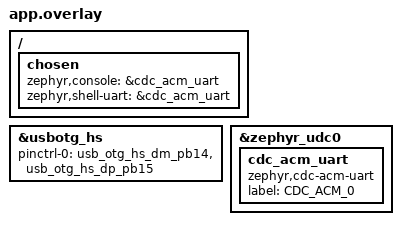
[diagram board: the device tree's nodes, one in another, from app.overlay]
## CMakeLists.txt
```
cmake_minimum_required(VERSION 3.20.0)
find_package(Zephyr REQUIRED HINTS $ENV{ZEPHYR_BASE})
project(trabalho_final)
target_sources(app PRIVATE src/main.c)
```

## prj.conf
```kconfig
# --- Habilitações Gerais de Subsistemas ---
CONFIG_GPIO=y
CONFIG_DEBUG=y

# --- Console, Serial e Shell ---
CONFIG_SERIAL=y
CONFIG_CONSOLE=y
CONFIG_SHELL=y
CONFIG_SHELL_LOG_BACKEND=y


# --- Stack USB e Console sobre USB (CDC_ACM) ---
CONFIG_USB_DEVICE_STACK=y
CONFIG_USB_DEVICE_PRODUCT="STM32F429 Hard Real-Time"
CONFIG_USB_CDC_ACM=y
CONFIG_USB_DEVICE_INITIALIZE_AT_BOOT=y

# --- Configurações de VID/PID para desenvolvimento ---
CONFIG_USB_DEVICE_VID=0x2FE3
CONFIG_USB_DEVICE_PID=0x0100
CONFIG_USB_DEVICE_MANUFACTURER="STM32F429 Hard RT"

# --- Módulos de Informação do Sistema ---
CONFIG_HEAP_MEM_POOL_SIZE=16384
CONFIG_THREAD_MONITOR=y
CONFIG_THREAD_NAME=y
CONFIG_THREAD_STACK_INFO=y
CONFIG_THREAD_ANALYZER=y
CONFIG_THREAD_ANALYZER_USE_PRINTK=y

# --- Configurações de Scheduling (corrigidas) ---
CONFIG_SCHED_THREAD_USAGE=y
CONFIG_SCHED_THREAD_USAGE_ALL=y

# --- Logs e Debug ---
CONFIG_LOG=y


# --- Configurações de Tempo Real Otimizadas ---
CONFIG_TIMESLICING=y
CONFIG_TIMESLICE_SIZE=5

# --- Precisão de Timing para Hard Real-Time ---
CONFIG_SYS_CLOCK_HW_CYCLES_PER_SEC=168000000
CONFIG_TIMER_RANDOM_GENERATOR=n
# CONFIG_TIMER_READS_ITS_FREQUENCY_AT_RUNTIME=y  # Removido - não existe

# --- Matemática e Geração de Números Aleatórios ---
CONFIG_ENTROPY_GENERATOR=y
CONFIG_TEST_RANDOM_GENERATOR=y

# --- Configurações de Memória Otimizadas ---
CONFIG_MAIN_STACK_SIZE=2048
CONFIG_CBPRINTF_FP_SUPPORT=y
CONFIG_KERNEL_MEM_POOL=y


# --- Configurações para reduzir latência ---
CONFIG_BOOT_BANNER=n
CONFIG_THREAD_CUSTOM_DATA=y

# --- Configurações de Floating Point ---
CONFIG_FPU=y
CONFIG_FPU_SHARING=y

# --- Configurações básicas para Hard Real-Time ---
# Configurações de Timer do Sistema
CONFIG_TICKLESS_KERNEL=y

# Configurações de Interrupções  
CONFIG_DYNAMIC_INTERRUPTS=y

# Configurações de Memória para Real-Time
CONFIG_MPU_STACK_GUARD=y
```

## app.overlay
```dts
/ {
	chosen {
		zephyr,console = &cdc_acm_uart;
		zephyr,shell-uart = &cdc_acm_uart;
	};
};

&usbotg_hs {
	pinctrl-0 = <&usb_otg_hs_dm_pb14 &usb_otg_hs_dp_pb15>;
	pinctrl-names = "default";
	status = "okay";
};

&zephyr_udc0 {
	cdc_acm_uart: cdc_acm_uart {
		compatible = "zephyr,cdc-acm-uart";
		label = "CDC_ACM_0";
	};
};
```

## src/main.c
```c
#include <zephyr/kernel.h>
#include <zephyr/drivers/gpio.h>
#include <zephyr/usb/usb_device.h>
#include <zephyr/logging/log.h>

LOG_MODULE_REGISTER(main, LOG_LEVEL_INF);

/* --- REFERÊNCIAS EXTERNAS --- */
extern int init_hard_realtime_filter(void);

/* --- TAREFA 1: PISCAR O LED (BAIXA PRIORIDADE) --- */
#define LED0_NODE DT_ALIAS(led0)
static const struct gpio_dt_spec led = GPIO_DT_SPEC_GET(LED0_NODE, gpios);

void blink_led_task(void)
{
    if (!gpio_is_ready_dt(&led)) {
        LOG_ERR("LED0 não está pronto");
        return;
    }
    
    gpio_pin_configure_dt(&led, GPIO_OUTPUT_ACTIVE);
    LOG_INF("LED de status iniciado");
    
    while (1) {
        gpio_pin_toggle_dt(&led);
        k_msleep(2000); // Pisca mais devagar para não interferir
    }
}

/* --- TAREFA 2: ACIONAMENTO PELO BOTÃO --- */
#define BUTTON0_NODE DT_ALIAS(sw0)
static const struct gpio_dt_spec button = GPIO_DT_SPEC_GET(BUTTON0_NODE, gpios);
static struct gpio_callback button_cb_data;
K_SEM_DEFINE(button_sem, 0, 1);

void button_pressed_callback(const struct device *dev, struct gpio_callback *cb, uint32_t pins)
{
    k_sem_give(&button_sem);
}

void button_action_task(void)
{
    uint32_t press_count = 0;
    
    while (1) {
        k_sem_take(&button_sem, K_FOREVER);
        press_count++;
        
        LOG_INF("Botao pressionado! Contagem: %u", press_count);
        
        // Indica pressionamento com LED por 100ms
        gpio_pin_set_dt(&led, 1);
        k_msleep(100);
        gpio_pin_set_dt(&led, 0);
        k_msleep(50);
        k_sem_reset(&button_sem);


    }
}

/* --- FUNÇÃO PRINCIPAL --- */
int main(void)
{
    // 1. Inicializa filtro hard real-time
    int ret = init_hard_realtime_filter();
    if (ret < 0) {
        LOG_ERR("Falha ao inicializar filtro hard real-time: %d", ret);
        LOG_ERR("Sistema continuara sem filtro hard real-time");
    } 
    
    // 2. Inicializa hardware do botão
    if (!gpio_is_ready_dt(&button)) {
        LOG_ERR("Botão não está pronto");
        return 0;
    }
    
    gpio_pin_configure_dt(&button, GPIO_INPUT);
    gpio_pin_interrupt_configure_dt(&button, GPIO_INT_EDGE_TO_ACTIVE);
    gpio_init_callback(&button_cb_data, button_pressed_callback, BIT(button.pin));
    gpio_add_callback(button.port, &button_cb_data);
    
    // 3. Sistema pronto!
    
   
    LOG_INF("Comandos shell disponiveis:");
    LOG_INF("  - 'sensor' - Comandos da tarefa soft real-time");
    LOG_INF("  - 'filter' - Comandos da tarefa hard real-time");
    LOG_INF("  - 'sysinfo' - Informacoes do sistema");
    
    return 0;
}

/* --- DEFINIÇÃO DAS THREADS COM PRIORIDADES HIERARQUICAS --- */
// Prioridade 2: Filtro hard real-time (definido em hard_realtime_filter.c)
// Prioridade 3: Amostragem ADC (definido em hard_realtime_filter.c)
// Prioridade 4: Sensor soft real-time (definido em sensor_task.c)
// Prioridade 7: Botão (responsividade)
// Prioridade 10: LED (menor prioridade)

K_THREAD_DEFINE(blink_led_tid, 512, blink_led_task, NULL, NULL, NULL, 10, 0, 0);
K_THREAD_DEFINE(button_action_tid, 512, button_action_task, NULL, NULL, NULL, 7, 0, 0);
```

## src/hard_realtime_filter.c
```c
#include <zephyr/kernel.h>
#include <zephyr/drivers/adc.h>
#include <zephyr/drivers/dac.h>
#include <zephyr/logging/log.h>
#include <zephyr/sys/ring_buffer.h>
#include <math.h>
#include <string.h>

LOG_MODULE_REGISTER(hard_filter, LOG_LEVEL_INF);

/* --- CONFIGURAÇÕES DO FILTRO HARD REAL-TIME --- */
#define SAMPLE_RATE_HZ 8000         // 8 kHz de amostragem
#define SAMPLE_PERIOD_US (1000000 / SAMPLE_RATE_HZ)  // 125 µs
#define HARD_DEADLINE_US 100        // Deadline rígido de 100µs
#define FILTER_ORDER 4              // Filtro IIR de 4ª ordem
#define CUTOFF_FREQ_HZ 1000         // Frequência de corte 1kHz

/* --- ESTRUTURAS DE DADOS --- */
struct filter_coeffs {
    float a[FILTER_ORDER + 1];      // Coeficientes do denominador
    float b[FILTER_ORDER + 1];      // Coeficientes do numerador
};

struct filter_state {
    float x[FILTER_ORDER + 1];      // Histórico de entradas
    float y[FILTER_ORDER + 1];      // Histórico de saídas
    uint32_t index;                 // Índice circular
};

/* --- CONFIGURAÇÃO DO HARDWARE --- */
#define ADC_NODE DT_ALIAS(adc)
#define DAC_NODE DT_ALIAS(dac)

#if DT_NODE_EXISTS(ADC_NODE)
static const struct device *adc_dev = DEVICE_DT_GET(ADC_NODE);
#endif

#if DT_NODE_EXISTS(DAC_NODE)
static const struct device *dac_dev = DEVICE_DT_GET(DAC_NODE);
#endif



/* --- VARIÁVEIS GLOBAIS --- */
static struct filter_coeffs coeffs;
static struct filter_state filter_state;
static struct k_timer sample_timer;
static K_SEM_DEFINE(sample_sem, 0, 1);
K_MSGQ_DEFINE(sample_msgq, sizeof(uint16_t), 32, 4);

/* --- ESTATÍSTICAS TEMPO REAL --- */
static uint32_t total_samples = 0;
static uint32_t missed_deadlines = 0;
static uint32_t max_processing_time_us = 0;
static uint32_t min_processing_time_us = UINT32_MAX;

/* --- INICIALIZAÇÃO DO FILTRO BUTTERWORTH PASSA-BAIXA --- */
static void init_butterworth_filter(void)
{
    // Coeficientes aproximados para filtro Butterworth 4ª ordem
    // Frequência de corte normalizada: fc/fs = 1000/8000 = 0.125
    // Estes são coeficientes aproximados para demonstração
    
    // Coeficientes do numerador (b)
    coeffs.b[0] = 0.0067f;
    coeffs.b[1] = 0.0268f;
    coeffs.b[2] = 0.0402f;
    coeffs.b[3] = 0.0268f;
    coeffs.b[4] = 0.0067f;
    
    // Coeficientes do denominador (a)
    coeffs.a[0] = 1.0000f;
    coeffs.a[1] = -2.3695f;
    coeffs.a[2] = 2.3140f;
    coeffs.a[3] = -1.0547f;
    coeffs.a[4] = 0.1874f;
    
    // Inicializa estado do filtro
    memset(&filter_state, 0, sizeof(filter_state));
    
    LOG_INF("Filtro Butterworth inicializado (fc=%d Hz, fs=%d Hz)", 
            CUTOFF_FREQ_HZ, SAMPLE_RATE_HZ);
}

/* --- APLICAÇÃO DO FILTRO IIR --- */
static float apply_filter(float input)
{
    uint32_t i = filter_state.index;
    
    // Armazena nova entrada
    filter_state.x[i] = input;
    
    // Calcula saída usando equação diferencial
    float output = 0.0f;
    
    // Parte do numerador (FIR)
    for (int n = 0; n <= FILTER_ORDER; n++) {
        uint32_t idx = (i + FILTER_ORDER - n) % (FILTER_ORDER + 1);
        output += coeffs.b[n] * filter_state.x[idx];
    }
    
    // Parte do denominador (IIR)
    for (int n = 1; n <= FILTER_ORDER; n++) {
        uint32_t idx = (i + FILTER_ORDER - n + 1) % (FILTER_ORDER + 1);
        output -= coeffs.a[n] * filter_state.y[idx];
    }
    
    // Armazena saída
    filter_state.y[i] = output;
    
    // Avança índice circular
    filter_state.index = (i + 1) % (FILTER_ORDER + 1);
    
    return output;
}

/* --- CALLBACK DO TIMER (INTERRUPT CONTEXT) --- */
static void sample_timer_handler(struct k_timer *timer)
{
    ARG_UNUSED(timer);
    // Sinaliza thread de processamento (não bloqueia)
    k_sem_give(&sample_sem);
}

/* --- TAREFA DE AMOSTRAGEM ADC (ALTA PRIORIDADE) --- */
static void adc_sampling_task(void *p1, void *p2, void *p3)
{
    ARG_UNUSED(p1);
    ARG_UNUSED(p2);
    ARG_UNUSED(p3);
    
#if DT_NODE_EXISTS(ADC_NODE)
    uint16_t sample_buffer[1];
    struct adc_sequence sequence = {
        .channels = BIT(0),
        .buffer = sample_buffer,
        .buffer_size = sizeof(sample_buffer),
        .resolution = 12,
        .oversampling = 0,
        .calibrate = false,
    };
    
    LOG_INF("Tarefa de amostragem ADC iniciada");
    
    while (1) {
        // Aguarda sinal do timer
        k_sem_take(&sample_sem, K_FOREVER);
        
        // Lê ADC (operação determinística)
        int ret = adc_read(adc_dev, &sequence);
        if (ret == 0) {
            // Envia amostra para processamento
            k_msgq_put(&sample_msgq, &sample_buffer[0], K_NO_WAIT);
        }
    }
#else
    while (1) {
        k_sem_take(&sample_sem, K_FOREVER);
        // Simula dados para teste
        uint16_t dummy_sample = 2048 + (total_samples % 100);
        k_msgq_put(&sample_msgq, &dummy_sample, K_NO_WAIT);
    }
#endif
}

/* --- TAREFA DE PROCESSAMENTO HARD REAL-TIME --- */
static void hard_realtime_filter_task(void *p1, void *p2, void *p3)
{
    ARG_UNUSED(p1);
    ARG_UNUSED(p2);
    ARG_UNUSED(p3);
    
    uint16_t raw_sample;
    uint32_t start_time, end_time, processing_time_us;
    
    LOG_INF("=== TAREFA HARD REAL-TIME INICIADA ===");
    LOG_INF("Deadline: %d us, Período: %d us", HARD_DEADLINE_US, SAMPLE_PERIOD_US);
    
    while (1) {
        // Aguarda nova amostra
        k_msgq_get(&sample_msgq, &raw_sample, K_FOREVER);
        
        start_time = k_cycle_get_32();
        
        // Converte ADC para float (-1.0 a 1.0)
        float input = (float)(raw_sample - 2048) / 2048.0f;
        
        // Aplica filtro digital
        float filtered = apply_filter(input);
        
        // Converte para DAC (0-4095)
        uint16_t dac_value = (uint16_t)((filtered + 1.0f) * 2048.0f);
        if (dac_value > 4095) dac_value = 4095;
        
        // Envia para DAC se disponível
#if DT_NODE_EXISTS(DAC_NODE)
        dac_write_value(dac_dev, 0, dac_value);
#endif
        
        end_time = k_cycle_get_32();
        processing_time_us = k_cyc_to_us_floor32(end_time - start_time);
        
        // Atualiza estatísticas
        total_samples++;
        if (processing_time_us > max_processing_time_us) {
            max_processing_time_us = processing_time_us;
        }
        if (processing_time_us < min_processing_time_us) {
            min_processing_time_us = processing_time_us;
        }
        
        // Verifica deadline HARD
        if (processing_time_us > HARD_DEADLINE_US) {
            missed_deadlines++;
            LOG_ERR("HARD DEADLINE PERDIDO! Amostra=%u, Tempo=%u us (limite=%u us)",
                    total_samples, processing_time_us, HARD_DEADLINE_US);
            
            // Em sistema real, seria necessário ação corretiva imediata
            // Por exemplo: reset do sistema, modo seguro, etc.
        }
        
        // Log periódico (sem afetar tempo real)
        //if ((total_samples % 1000) == 0) {
        //    LOG_INF("Amostras processadas: %u, Perdas: %u, Último tempo: %u us",
        //            total_samples, missed_deadlines, processing_time_us);
        //}
    }
}

/* --- FUNÇÕES DE INTERFACE PARA SHELL --- */
void get_filter_stats(uint32_t *total, uint32_t *missed, uint32_t *max_time, uint32_t *min_time)
{
    *total = total_samples;
    *missed = missed_deadlines;
    *max_time = max_processing_time_us;
    *min_time = (min_processing_time_us == UINT32_MAX) ? 0 : min_processing_time_us;
}

void get_filter_info(uint32_t *sample_rate, uint32_t *cutoff_freq, uint32_t *deadline_us)
{
    *sample_rate = SAMPLE_RATE_HZ;
    *cutoff_freq = CUTOFF_FREQ_HZ;
    *deadline_us = HARD_DEADLINE_US;
}

/* --- INICIALIZAÇÃO DO SISTEMA --- */
int init_hard_realtime_filter(void)
{
#if DT_NODE_EXISTS(ADC_NODE)
    /* --- E cole aqui, dentro do bloco #if --- */
    static const struct adc_channel_cfg adc_cfg = {
        .gain = ADC_GAIN_1,
        .reference = ADC_REF_INTERNAL,
        .acquisition_time = ADC_ACQ_TIME_DEFAULT,
        .channel_id = 0,
        .differential = 0,
    };

    if (!device_is_ready(adc_dev)) { ... }

    int ret = adc_channel_setup(adc_dev, &adc_cfg); // <-- Onde ela é usada
#else
    LOG_WRN("ADC não disponível - modo simulação");
#endif

#if DT_NODE_EXISTS(DAC_NODE)
    if (!device_is_ready(dac_dev)) {
        LOG_ERR("DAC não está pronto");
        return -ENODEV;
    }
    
    // Configura DAC
    struct dac_channel_cfg dac_cfg = {
        .channel_id = 0,
        .resolution = 12,
        .buffered = false,
    };
    
    ret = dac_channel_setup(dac_dev, &dac_cfg);
    if (ret < 0) {
        LOG_ERR("Erro ao configurar DAC: %d", ret);
        return ret;
    }
#else
    LOG_WRN("DAC não disponível - modo simulação");
#endif
    
    // Inicializa filtro
    init_butterworth_filter();
    
    // Inicializa timer
    k_timer_init(&sample_timer, sample_timer_handler, NULL);
    
    // Inicia timer periódico
    k_timer_start(&sample_timer, K_USEC(SAMPLE_PERIOD_US), K_USEC(SAMPLE_PERIOD_US));
    
    
    return 0;
}

/* --- DEFINIÇÃO DAS THREADS COM PRIORIDADES CRÍTICAS --- */
// Prioridade 2: Processamento hard real-time (mais alta)
// Prioridade 3: Amostragem ADC (alta)
K_THREAD_DEFINE(adc_sampling_tid, 1024, adc_sampling_task, NULL, NULL, NULL, 3, 0, 0);
K_THREAD_DEFINE(hard_filter_tid, 2048, hard_realtime_filter_task, NULL, NULL, NULL, 2, 0, 0);
```

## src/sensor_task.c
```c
// src/sensor_task.c - Uma tarefa de tempo real soft (com correções de warnings)
#include <zephyr/kernel.h>
#include <zephyr/drivers/gpio.h>
#include <zephyr/logging/log.h>
#include <zephyr/random/random.h>

LOG_MODULE_REGISTER(sensor_task, LOG_LEVEL_INF);

/* --- ESTRUTURA DE DADOS DO SENSOR --- */
struct sensor_reading {
    uint32_t timestamp;
    float temperature;
    float humidity;
    uint32_t sequence;
};

/* --- CONFIGURAÇÕES DA TAREFA TEMPO REAL SOFT --- */
#define SENSOR_PERIOD_MS 200        // 5Hz - leitura a cada 200ms
#define SENSOR_DEADLINE_MS 150      // Deadline de 150ms (soft real-time)
#define MAX_READINGS 50             // Buffer para últimas 50 leituras

/* --- VARIÁVEIS GLOBAIS --- */
static struct sensor_reading readings[MAX_READINGS];
static uint32_t reading_index = 0;
static uint32_t total_readings = 0;
static uint32_t missed_deadlines = 0;
static uint32_t max_processing_time_us = 0;

/* --- TAREFA DE LEITURA PERIÓDICA DE SENSORES (SOFT REAL-TIME) --- */
void sensor_reading_task(void)
{
    uint32_t start_time, processing_time;
    uint32_t next_period = k_uptime_get_32();
    
    LOG_INF("=== TAREFA SOFT REAL-TIME INICIADA ===");
    LOG_INF("Periodo: %d ms, Deadline: %d ms", SENSOR_PERIOD_MS, SENSOR_DEADLINE_MS);
    
    while (1) {
        start_time = k_cycle_get_32();
        
        // Simula leitura de sensores de temperatura e umidade
        struct sensor_reading *current = &readings[reading_index];
        
        current->timestamp = k_uptime_get_32();
        current->sequence = total_readings++;
        
        // Simula sensor de temperatura (20-30°C)
        current->temperature = 25.0f + (float)(sys_rand32_get() % 1000) / 100.0f - 5.0f;
        
        // Simula sensor de umidade (40-80%)
        current->humidity = 60.0f + (float)(sys_rand32_get() % 4000) / 100.0f - 20.0f;
        
        // Simula tempo de processamento variável (leitura I2C, ADC, etc.)
        // Tempo real soft: pode ocasionalmente perder deadline
        uint32_t processing_delay = sys_rand32_get() % 100000; // 0-100ms
        k_usleep(processing_delay); 

        
        // Calcula tempo de processamento
        processing_time = k_cycle_get_32() - start_time;
        uint32_t processing_time_us = k_cyc_to_us_floor32(processing_time);
        
        // Atualiza estatísticas
        if (processing_time_us > max_processing_time_us) {
            max_processing_time_us = processing_time_us;
        }
        
        // Verifica se perdeu o deadline (característica soft real-time)
        if (processing_time_us > (SENSOR_DEADLINE_MS * 1000)) {
            missed_deadlines++;
            LOG_WRN("Deadline perdido! Seq=%u, Tempo=%u us (limite=%u us)",
                    current->sequence, processing_time_us, SENSOR_DEADLINE_MS * 1000);
        }
        
        // Log periódico dos dados - CORREÇÃO: cast explícito para double
        //if ((total_readings % 10) == 0) {
        //    LOG_INF("Leitura #%u: T=%.1f°C, H=%.1f%%, tempo=%u us",
        //            current->sequence, (double)current->temperature, (double)current->humidity, processing_time_us);
        //}
        
        // Avança índice circular
        reading_index = (reading_index + 1) % MAX_READINGS;
        
        // Aguarda próximo período (característica periódica)
        next_period += SENSOR_PERIOD_MS;
        k_sleep(K_TIMEOUT_ABS_MS(next_period));
    }
}

/* --- FUNÇÃO PARA OBTER ESTATÍSTICAS (PARA O SHELL) --- */
void get_sensor_stats(uint32_t *total, uint32_t *missed, uint32_t *max_time_us)
{
    *total = total_readings;
    *missed = missed_deadlines;
    *max_time_us = max_processing_time_us;
}

/* --- FUNÇÃO PARA OBTER ÚLTIMA LEITURA --- */
struct sensor_reading* get_last_reading(void)
{
    if (total_readings == 0) {
        return NULL;
    }
    
    uint32_t last_index = (reading_index + MAX_READINGS - 1) % MAX_READINGS;
    return &readings[last_index];
}

/* --- FUNÇÃO PARA OBTER MÚLTIPLAS LEITURAS --- */
int get_recent_readings(struct sensor_reading *buffer, int max_count)
{
    int count = 0;
    int available = (total_readings < MAX_READINGS) ? total_readings : MAX_READINGS;
    
    if (available == 0) {
        return 0;
    }
    
    // Copia as leituras mais recentes
    for (int i = 0; i < available && count < max_count; i++) {
        int index = (reading_index + MAX_READINGS - 1 - i) % MAX_READINGS;
        buffer[count++] = readings[index];
    }
    
    return count;
}

/* --- DEFINIÇÃO DA THREAD COM PRIORIDADE ALTA (TEMPO REAL) --- */
K_THREAD_DEFINE(sensor_tid, 1024, sensor_reading_task, NULL, NULL, NULL, 4, 0, 0);
```

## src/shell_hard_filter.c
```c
// src/shell_hard_filter.c - Comandos shell para filtro hard real-time
#include <zephyr/kernel.h>
#include <zephyr/shell/shell.h>
#include <zephyr/logging/log.h>
#include <stdlib.h>
#include <math.h>
LOG_MODULE_REGISTER(shell_hard_filter, LOG_LEVEL_INF);

/* --- REFERÊNCIAS EXTERNAS --- */
extern void get_filter_stats(uint32_t *total, uint32_t *missed, uint32_t *max_time, uint32_t *min_time);
extern void get_filter_info(uint32_t *sample_rate, uint32_t *cutoff_freq, uint32_t *deadline_us);

/* --- COMANDO: ESTATÍSTICAS DO FILTRO HARD REAL-TIME --- */
static int cmd_filter_stats(const struct shell *sh, size_t argc, char **argv)
{
    uint32_t total, missed, max_time, min_time;
    get_filter_stats(&total, &missed, &max_time, &min_time);
    
    shell_print(sh, "=== ESTATISTICAS FILTRO HARD REAL-TIME ===");
    shell_print(sh, "Total de amostras: %u", total);
    shell_print(sh, "Deadlines perdidos: %u", missed);
    shell_print(sh, "Tempo processamento:");
    shell_print(sh, "  Minimo: %u us", min_time);
    shell_print(sh, "  Maximo: %u us", max_time);
    
    if (total > 0) {
        float miss_rate = (float)missed / total * 100.0f;
        shell_print(sh, "Taxa de perda: %.4f%%", (double)miss_rate);
        
        // Para hard real-time, QUALQUER perda é crítica
        if (missed == 0) {
            shell_print(sh, "Status: PERFEITO (0 perdas) - Hard Real-Time OK");
        } else {
            shell_print(sh, "Status: FALHA CRITICA (%u perdas) - Hard Real-Time VIOLADO", missed);
            shell_print(sh, "ACAO NECESSARIA: Sistema nao atende requisitos hard real-time");
        }
        
        // Análise do jitter
        if (max_time > 0 && min_time > 0) {
            uint32_t jitter = max_time - min_time;
            shell_print(sh, "Jitter: %u us", jitter);
            if (jitter > 20) {
                shell_print(sh, "AVISO: Jitter alto pode indicar problemas de determinismo");
            }
        }
    }
    
    return 0;
}

/* --- COMANDO: INFORMAÇÕES DO FILTRO --- */
static int cmd_filter_info(const struct shell *sh, size_t argc, char **argv)
{
    uint32_t sample_rate, cutoff_freq, deadline_us;
    get_filter_info(&sample_rate, &cutoff_freq, &deadline_us);
    
    shell_print(sh, "=== INFORMACOES DO FILTRO HARD REAL-TIME ===");
    shell_print(sh, "Tipo: Filtro IIR Butterworth passa-baixa");
    shell_print(sh, "Ordem: 4");
    shell_print(sh, "Frequencia de amostragem: %u Hz", sample_rate);
    shell_print(sh, "Frequencia de corte: %u Hz", cutoff_freq);
    shell_print(sh, "Periodo de amostragem: %u us", 1000000 / sample_rate);
    shell_print(sh, "Deadline HARD: %u us", deadline_us);
    shell_print(sh, "Prioridade: 2 (maxima)");
    
    shell_print(sh, "");
    shell_print(sh, "Caracteristicas Hard Real-Time:");
    shell_print(sh, "  - Deadline rigido de %u us", deadline_us);
    shell_print(sh, "  - Processamento deterministico");
    shell_print(sh, "  - Nenhuma perda de deadline tolerada");
    shell_print(sh, "  - Tempo de resposta garantido");
    shell_print(sh, "  - Preempcao de todas as outras tarefas");
    
    shell_print(sh, "");
    shell_print(sh, "Fluxo de dados:");
    shell_print(sh, "  ADC -> Filtro Digital -> DAC");
    
    return 0;
}

/* --- COMANDO: MONITORAMENTO EM TEMPO REAL --- */
static int cmd_filter_monitor(const struct shell *sh, size_t argc, char **argv)
{
    int duration = 10; // segundos
    
    if (argc > 1) {
        duration = atoi(argv[1]);
        if (duration < 5 || duration > 60) {
            shell_error(sh, "Duracao deve estar entre 5 e 60 segundos");
            return -EINVAL;
        }
    }
    
    shell_print(sh, "=== MONITORAMENTO HARD REAL-TIME (%d segundos) ===", duration);
    shell_print(sh, "Monitorando violacoes de deadline...");
    
    uint32_t start_time = k_uptime_get_32();
    uint32_t last_check = start_time;
    uint32_t last_total = 0;
    uint32_t last_missed = 0;
    
    while ((k_uptime_get_32() - start_time) < (duration * 1000)) {
        // Verifica estatísticas a cada segundo
        if ((k_uptime_get_32() - last_check) >= 1000) {
            uint32_t total, missed, max_time, min_time;
            get_filter_stats(&total, &missed, &max_time, &min_time);
            
            uint32_t new_samples = total - last_total;
            uint32_t new_missed = missed - last_missed;
            
            shell_print(sh, "T+%02d: Amostras=%u (+%u/s), Perdas=%u (+%u), Max=%uus, Min=%uus",
                       (k_uptime_get_32() - start_time) / 1000,
                       total, new_samples, missed, new_missed, max_time, min_time);
            
            if (new_missed > 0) {
                shell_print(sh, "     !!! VIOLACAO HARD REAL-TIME DETECTADA !!!");
            }
            
            last_check = k_uptime_get_32();
            last_total = total;
            last_missed = missed;
        }
        
        k_msleep(100);
    }
    
    shell_print(sh, "Monitoramento finalizado");
    
    // Relatório final
    uint32_t total, missed, max_time, min_time;
    get_filter_stats(&total, &missed, &max_time, &min_time);
    
    shell_print(sh, "");
    shell_print(sh, "=== RELATORIO FINAL ===");
    shell_print(sh, "Amostras processadas: %u", total);
    shell_print(sh, "Deadlines perdidos: %u", missed);
    shell_print(sh, "Taxa de amostragem media: %.1f Hz", (double)total / duration);
    
    if (missed == 0) {
        shell_print(sh, "RESULTADO: Sistema atende requisitos hard real-time");
    } else {
        shell_print(sh, "RESULTADO: Sistema FALHOU nos requisitos hard real-time");
    }
    
    return 0;
}

/* --- COMANDO: TESTE DE STRESS --- */
static int cmd_filter_stress(const struct shell *sh, size_t argc, char **argv)
{
    shell_print(sh, "=== TESTE DE STRESS HARD REAL-TIME ===");
    shell_print(sh, "Iniciando teste de stress por 30 segundos...");
    shell_print(sh, "Este teste adiciona carga ao sistema para verificar determinismo");
    
    // Cria carga adicional no sistema
    uint32_t start_time = k_uptime_get_32();
    uint32_t stress_count = 0;
    
    while ((k_uptime_get_32() - start_time) < 30000) {
        // Adiciona trabalho computacional
        volatile float dummy = 0.0f;
        for (int i = 0; i < 1000; i++) {
            dummy += sinf(i * 0.1f);
        }
        stress_count++;
        
        // Verifica estatísticas periodicamente
        if ((stress_count % 100) == 0) {
            uint32_t total, missed, max_time, min_time;
            get_filter_stats(&total, &missed, &max_time, &min_time);
            
            shell_print(sh, "Stress %u: Amostras=%u, Perdas=%u, Max=%uus",
                       stress_count, total, missed, max_time);
        }
        
        k_msleep(10);
    }
    
    shell_print(sh, "Teste de stress finalizado");
    
    uint32_t total, missed, max_time, min_time;
    get_filter_stats(&total, &missed, &max_time, &min_time);
    
    shell_print(sh, "");
    shell_print(sh, "=== RESULTADO DO TESTE DE STRESS ===");
    shell_print(sh, "Iteracoes de stress: %u", stress_count);
    shell_print(sh, "Amostras processadas: %u", total);
    shell_print(sh, "Deadlines perdidos: %u", missed);
    
    if (missed == 0) {
        shell_print(sh, "RESULTADO: Sistema mantem hard real-time sob stress");
    } else {
        shell_print(sh, "RESULTADO: Sistema perde hard real-time sob stress");
        shell_print(sh, "Necessario otimizar prioridades ou reduzir carga");
    }
    
    return 0;
}

/* --- COMANDO: ANÁLISE DE LATÊNCIA --- */
static int cmd_filter_latency(const struct shell *sh, size_t argc, char **argv)
{
    shell_print(sh, "=== ANALISE DE LATENCIA HARD REAL-TIME ===");
    
    uint32_t sample_rate, cutoff_freq, deadline_us;
    get_filter_info(&sample_rate, &cutoff_freq, &deadline_us);
    
    uint32_t total, missed, max_time, min_time;
    get_filter_stats(&total, &missed, &max_time, &min_time);
    
    shell_print(sh, "Deadline configurado: %u us", deadline_us);
    shell_print(sh, "Latencia minima: %u us", min_time);
    shell_print(sh, "Latencia maxima: %u us", max_time);
    
    if (total > 0) {
        uint32_t jitter = max_time - min_time;
        shell_print(sh, "Jitter: %u us", jitter);
        
        float deadline_margin = ((float)(deadline_us - max_time) / deadline_us) * 100.0f;
        shell_print(sh, "Margem de deadline: %.1f%%", (double)deadline_margin);
        
        shell_print(sh, "");
        shell_print(sh, "Analise de determinismo:");
        if (jitter < 10) {
            shell_print(sh, "  Jitter: EXCELENTE (< 10us)");
        } else if (jitter < 30) {
            shell_print(sh, "  Jitter: BOM (< 30us)");
        } else {
            shell_print(sh, "  Jitter: RUIM (> 30us) - Verificar sistema");
        }
        
        if (deadline_margin > 20.0f) {
            shell_print(sh, "  Margem: SEGURA (> 20%%)");
        } else if (deadline_margin > 10.0f) {
            shell_print(sh, "  Margem: ACEITAVEL (> 10%%)");
        } else {
            shell_print(sh, "  Margem: CRITICA (< 10%%) - Risco de violacao");
        }
    }
    
    return 0;
}

/* --- DEFINIÇÃO DOS SUBCOMANDOS --- */
SHELL_STATIC_SUBCMD_SET_CREATE(sub_filter,
    SHELL_CMD(stats, NULL, "Estatisticas do filtro hard real-time", cmd_filter_stats),
    SHELL_CMD(info, NULL, "Informacoes do filtro", cmd_filter_info),
    SHELL_CMD(monitor, NULL, "Monitor em tempo real [duracao_seg]", cmd_filter_monitor),
    SHELL_CMD(stress, NULL, "Teste de stress do sistema", cmd_filter_stress),
    SHELL_CMD(latency, NULL, "Analise de latencia e jitter", cmd_filter_latency),
    SHELL_SUBCMD_SET_END
);

/* --- REGISTRO DO COMANDO PRINCIPAL --- */
SHELL_CMD_REGISTER(filter, &sub_filter, "Comandos do filtro hard real-time", NULL);
```

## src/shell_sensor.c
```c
// src/shell_sensor.c - Comandos shell para a tarefa de sensor
#include <zephyr/kernel.h>
#include <zephyr/shell/shell.h>
#include <zephyr/logging/log.h>
#include <stdlib.h>  // Added for atoi function

LOG_MODULE_REGISTER(shell_sensor, LOG_LEVEL_INF);

/* --- REFERÊNCIAS EXTERNAS --- */
extern void get_sensor_stats(uint32_t *total, uint32_t *missed, uint32_t *max_time_us);
extern struct sensor_reading* get_last_reading(void);
extern int get_recent_readings(struct sensor_reading *buffer, int max_count);

struct sensor_reading {
    uint32_t timestamp;
    float temperature;
    float humidity;
    uint32_t sequence;
};

/* --- COMANDO: ESTATÍSTICAS DA TAREFA --- */
static int cmd_sensor_stats(const struct shell *sh, size_t argc, char **argv)
{
    uint32_t total, missed, max_time_us;
    get_sensor_stats(&total, &missed, &max_time_us);
    
    shell_print(sh, "=== ESTATISTICAS DA TAREFA SOFT REAL-TIME ===");
    shell_print(sh, "Total de leituras: %u", total);
    shell_print(sh, "Deadlines perdidos: %u", missed);
    shell_print(sh, "Tempo max processamento: %u us", max_time_us);
    
    if (total > 0) {
        float miss_rate = (float)missed / total * 100.0f;
        shell_print(sh, "Taxa de perda: %.2f%%", (double)miss_rate);  // Fixed: cast to double
        
        if (miss_rate < 5.0f) {
            shell_print(sh, "Status: EXCELENTE (< 5%% perdas)");
        } else if (miss_rate < 15.0f) {
            shell_print(sh, "Status: BOM (< 15%% perdas)");
        } else {
            shell_print(sh, "Status: ATENCAO (> 15%% perdas)");
        }
    }
    
    return 0;
}

/* --- COMANDO: ÚLTIMA LEITURA --- */
static int cmd_sensor_last(const struct shell *sh, size_t argc, char **argv)
{
    struct sensor_reading *reading = get_last_reading();
    
    if (reading == NULL) {
        shell_print(sh, "Nenhuma leitura disponivel ainda");
        return 0;
    }
    
    shell_print(sh, "=== ULTIMA LEITURA ===");
    shell_print(sh, "Sequencia: %u", reading->sequence);
    shell_print(sh, "Timestamp: %u ms", reading->timestamp);
    shell_print(sh, "Temperatura: %.1f °C", (double)reading->temperature);  // Fixed: cast to double
    shell_print(sh, "Umidade: %.1f %%", (double)reading->humidity);  // Fixed: cast to double
    shell_print(sh, "Idade: %u ms", k_uptime_get_32() - reading->timestamp);
    
    return 0;
}

/* --- COMANDO: MÚLTIPLAS LEITURAS --- */
static int cmd_sensor_history(const struct shell *sh, size_t argc, char **argv)
{
    int count = 5; // padrão: 5 leituras
    
    if (argc > 1) {
        count = atoi(argv[1]);
        if (count < 1 || count > 20) {
            shell_error(sh, "Numero de leituras deve estar entre 1 e 20");
            return -EINVAL;
        }
    }
    
    struct sensor_reading buffer[20];
    int readings_count = get_recent_readings(buffer, count);
    
    if (readings_count == 0) {
        shell_print(sh, "Nenhuma leitura disponivel");
        return 0;
    }
    
    shell_print(sh, "=== HISTORICO DE LEITURAS (ultimas %d) ===", readings_count);
    shell_print(sh, "Seq   | Timestamp | Temp(°C) | Umid(%%) | Idade(ms)");
    shell_print(sh, "------|-----------|----------|---------|----------");
    
    uint32_t current_time = k_uptime_get_32();
    for (int i = 0; i < readings_count; i++) {
        shell_print(sh, "%5u | %9u | %7.1f  | %6.1f  | %8u",
                    buffer[i].sequence, buffer[i].timestamp,
                    (double)buffer[i].temperature, (double)buffer[i].humidity,  // Fixed: cast to double
                    current_time - buffer[i].timestamp);
    }
    
    return 0;
}

/* --- COMANDO: INFORMAÇÕES DA TAREFA --- */
static int cmd_sensor_info(const struct shell *sh, size_t argc, char **argv)
{
    shell_print(sh, "=== INFORMACOES DA TAREFA SOFT REAL-TIME ===");
    shell_print(sh, "Tipo: Leitura periodica de sensores");
    shell_print(sh, "Periodo: 200 ms (5 Hz)");
    shell_print(sh, "Deadline: 150 ms (soft real-time)");
    shell_print(sh, "Prioridade: 4 (alta)");
    shell_print(sh, "Buffer: 50 leituras");
    shell_print(sh, "Sensores simulados:");
    shell_print(sh, "  - Temperatura: 20-30°C");
    shell_print(sh, "  - Umidade: 40-80%%");
    shell_print(sh, "Caracteristicas soft real-time:");
    shell_print(sh, "  - Pode ocasionalmente perder deadlines");
    shell_print(sh, "  - Degrada graciosamente sob carga");
    shell_print(sh, "  - Mantem precisao temporal media");
    
    return 0;
}

/* --- COMANDO: MONITORAMENTO EM TEMPO REAL --- */
static int cmd_sensor_monitor(const struct shell *sh, size_t argc, char **argv)
{
    int duration = 15; // segundos
    
    if (argc > 1) {
        duration = atoi(argv[1]);
        if (duration < 5 || duration > 60) {
            shell_error(sh, "Duracao deve estar entre 5 e 60 segundos");
            return -EINVAL;
        }
    }
    
    shell_print(sh, "=== MONITORAMENTO EM TEMPO REAL (%d segundos) ===", duration);
    shell_print(sh, "Monitoramento automatico - atualizacao a cada 3 segundos");
    
    uint32_t start_time = k_uptime_get_32();
    uint32_t last_check = start_time;
    uint32_t last_total = 0;
    
    while ((k_uptime_get_32() - start_time) < (duration * 1000)) {
        // Atualiza estatísticas a cada 3 segundos
        if ((k_uptime_get_32() - last_check) >= 3000) {
            uint32_t total, missed, max_time_us;
            get_sensor_stats(&total, &missed, &max_time_us);
            
            struct sensor_reading *last = get_last_reading();
            
            shell_print(sh, "T+%02d: Total=%u (+%u), Perdas=%u, Max=%uus, Ultima=%.1f°C",
                       (k_uptime_get_32() - start_time) / 1000,
                       total, total - last_total, missed, max_time_us,
                       last ? (double)last->temperature : 0.0);  // Fixed: cast to double
            
            last_check = k_uptime_get_32();
            last_total = total;
        }
        
        k_msleep(100);
    }
    
    shell_print(sh, "Monitoramento finalizado");
    return 0;
}

/* --- DEFINIÇÃO DOS SUBCOMANDOS --- */
SHELL_STATIC_SUBCMD_SET_CREATE(sub_sensor,
    SHELL_CMD(stats, NULL, "Estatisticas da tarefa", cmd_sensor_stats),
    SHELL_CMD(last, NULL, "Ultima leitura", cmd_sensor_last),
    SHELL_CMD(history, NULL, "Historico [num_leituras]", cmd_sensor_history),
    SHELL_CMD(info, NULL, "Informacoes da tarefa", cmd_sensor_info),
    SHELL_CMD(monitor, NULL, "Monitor em tempo real [duracao_seg]", cmd_sensor_monitor),
    SHELL_SUBCMD_SET_END
);

/* --- REGISTRO DO COMANDO PRINCIPAL --- */
SHELL_CMD_REGISTER(sensor, &sub_sensor, "Comandos da tarefa de sensor", NULL);
```

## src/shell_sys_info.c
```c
#include <zephyr/kernel.h>
#include <zephyr/shell/shell.h>
#include <zephyr/version.h>
#include <stdlib.h>

#ifdef CONFIG_THREAD_ANALYZER
#include <zephyr/debug/thread_analyzer.h>
#endif

// Função para mostrar informações básicas do sistema
static int cmd_sysinfo_general(const struct shell *sh, size_t argc, char **argv)
{
    shell_print(sh, "Informacoes Gerais do Sistema:");
    shell_print(sh, "  Versao do Kernel: %s", KERNEL_VERSION_STRING);
    shell_print(sh, "  Ticks por segundo: %d", CONFIG_SYS_CLOCK_TICKS_PER_SEC);
    shell_print(sh, "  Uptime: %lld ms", k_uptime_get());
    
    // Informações básicas sem APIs específicas de memória
    shell_print(sh, "  Heap configurado: %d bytes", CONFIG_HEAP_MEM_POOL_SIZE);
    
    return 0;
}

// Função para mostrar informações das threads
static void print_thread_info(const struct k_thread *thread, void *user_data)
{
    const struct shell *sh = (const struct shell *)user_data;
    k_tid_t tid = (k_tid_t)thread;
    const char *name;

    name = k_thread_name_get(tid);
    if (name == NULL) {
        name = "<sem nome>";
    }

    // Simplificando - apenas mostra nome e prioridade
    shell_print(sh, "  - %-20s | Prio: %d", name, k_thread_priority_get(tid));
}

static int cmd_sysinfo_tasks(const struct shell *sh, size_t argc, char **argv)
{
    shell_print(sh, "Tarefas (Threads) do Sistema:");
    k_thread_foreach(print_thread_info, (void *)sh);
    return 0;
}

#ifdef CONFIG_THREAD_ANALYZER
static int cmd_sysinfo_runtime(const struct shell *sh, size_t argc, char **argv)
{
    shell_print(sh, "Analise de Runtime das Tarefas:");
    thread_analyzer_print(0); // CPU 0 para single-core
    return 0;
}
#endif

// Função para mostrar informações sobre o stack das threads
static int cmd_sysinfo_stack(const struct shell *sh, size_t argc, char **argv)
{
    shell_print(sh, "Informacoes de Stack das Threads:");
    shell_print(sh, "  (Funcionalidade limitada - verifique manualmente)");
    return 0;
}

// Comando para testar o sistema
static int cmd_sysinfo_test(const struct shell *sh, size_t argc, char **argv)
{
    shell_print(sh, "Teste do Sistema:");
    shell_print(sh, "  Shell funcionando: OK");
    shell_print(sh, "  USB Console: OK");
    shell_print(sh, "  Timestamp: %lld ms", k_uptime_get());
    return 0;
}

// Definição dos subcomandos
SHELL_STATIC_SUBCMD_SET_CREATE(sub_sysinfo,
    SHELL_CMD(general, NULL, "Mostra info geral do sistema.", cmd_sysinfo_general),
    SHELL_CMD(tasks, NULL, "Lista as tarefas do sistema.", cmd_sysinfo_tasks),
    SHELL_CMD(stack, NULL, "Mostra info de stack.", cmd_sysinfo_stack),
    SHELL_CMD(test, NULL, "Testa o sistema.", cmd_sysinfo_test),
#ifdef CONFIG_THREAD_ANALYZER
    SHELL_CMD(runtime, NULL, "Mostra info de runtime.", cmd_sysinfo_runtime),
#endif
    SHELL_SUBCMD_SET_END
);

// Registro do comando principal
SHELL_CMD_REGISTER(sysinfo, &sub_sysinfo, "Comandos de info do sistema.", NULL);
```
